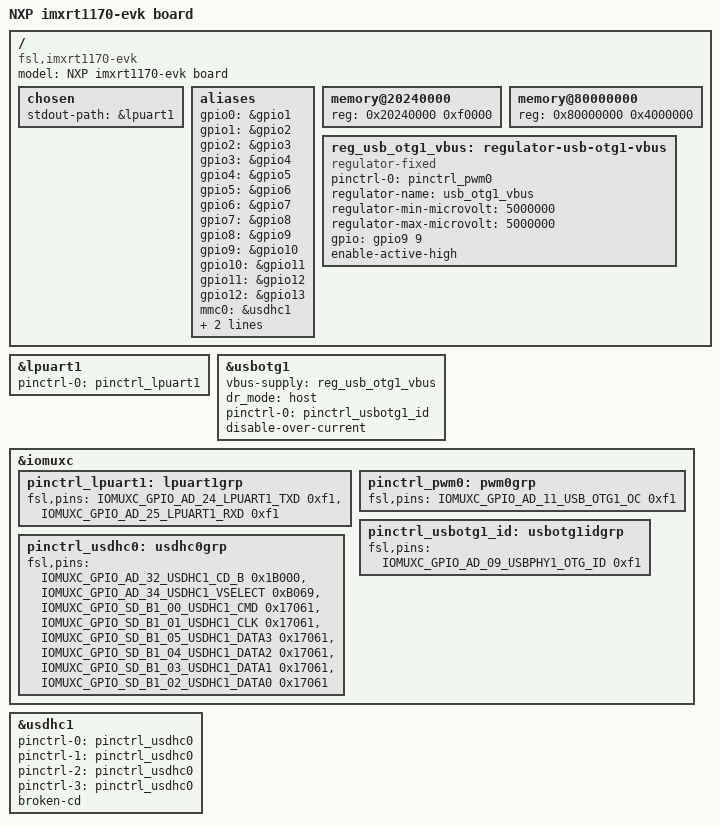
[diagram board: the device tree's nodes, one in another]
// SPDX-License-Identifier: (GPL-2.0+ OR BSD-3-Clause)
/*
 * Copyright (C) 2022
 * Author(s):  Jesse Taube <Mr.Bossman075@gmail.com>
 */

/dts-v1/;
#include "imxrt1170.dtsi"
#include "imxrt1170-pinfunc.h"

/ {
	model = "NXP imxrt1170-evk board";
	compatible = "fsl,imxrt1170-evk", "fsl,imxrt1170";

	chosen {
		stdout-path = &lpuart1;
	};

	aliases {
		gpio0 = &gpio1;
		gpio1 = &gpio2;
		gpio2 = &gpio3;
		gpio3 = &gpio4;
		gpio4 = &gpio5;
		gpio5 = &gpio6;
		gpio6 = &gpio7;
		gpio7 = &gpio8;
		gpio8 = &gpio9;
		gpio9 = &gpio10;
		gpio10 = &gpio11;
		gpio11 = &gpio12;
		gpio12 = &gpio13;
		mmc0 = &usdhc1;
		serial0 = &lpuart1;
		usbphy0 = &usbphy1;
	};

	memory@20240000 {
		device_type = "memory";
		reg = <0x20240000 0xf0000>;
	};

	memory@80000000 {
		device_type = "memory";
		reg = <0x80000000 0x4000000>;
	};

	reg_usb_otg1_vbus: regulator-usb-otg1-vbus {
		compatible = "regulator-fixed";
		pinctrl-names = "default";
		pinctrl-0 = <&pinctrl_pwm0>;
		regulator-name = "usb_otg1_vbus";
		regulator-min-microvolt = <5000000>;
		regulator-max-microvolt = <5000000>;
		gpio = <&gpio9 9 GPIO_ACTIVE_HIGH>;
		enable-active-high;
	};
};

&lpuart1 { /* console */
	pinctrl-names = "default";
	pinctrl-0 = <&pinctrl_lpuart1>;
	status = "okay";
};


&usbotg1 {
	vbus-supply = <&reg_usb_otg1_vbus>;
	dr_mode = "host";
	pinctrl-names = "default";
	pinctrl-0 = <&pinctrl_usbotg1_id>;
	disable-over-current;
	status = "okay";
};

&iomuxc {
	pinctrl_lpuart1: lpuart1grp {
		fsl,pins = <IOMUXC_GPIO_AD_24_LPUART1_TXD 0xf1>,
			   <IOMUXC_GPIO_AD_25_LPUART1_RXD 0xf1>;
	};

	pinctrl_pwm0: pwm0grp {
		fsl,pins = <IOMUXC_GPIO_AD_11_USB_OTG1_OC 0xf1>;
	};

	pinctrl_usbotg1_id: usbotg1idgrp {
		fsl,pins = <IOMUXC_GPIO_AD_09_USBPHY1_OTG_ID 0xf1>;
	};

	pinctrl_usdhc0: usdhc0grp {
		fsl,pins = <IOMUXC_GPIO_AD_32_USDHC1_CD_B		0x1B000>,
			   <IOMUXC_GPIO_AD_34_USDHC1_VSELECT		0xB069>,
			   <IOMUXC_GPIO_SD_B1_00_USDHC1_CMD		0x17061>,
			   <IOMUXC_GPIO_SD_B1_01_USDHC1_CLK		0x17061>,
			   <IOMUXC_GPIO_SD_B1_05_USDHC1_DATA3		0x17061>,
			   <IOMUXC_GPIO_SD_B1_04_USDHC1_DATA2		0x17061>,
			   <IOMUXC_GPIO_SD_B1_03_USDHC1_DATA1		0x17061>,
			   <IOMUXC_GPIO_SD_B1_02_USDHC1_DATA0		0x17061>;
	};
};

&usdhc1 {
	pinctrl-names = "default", "state_100mhz", "state_200mhz", "sleep";
	pinctrl-0 = <&pinctrl_usdhc0>;
	pinctrl-1 = <&pinctrl_usdhc0>;
	pinctrl-2 = <&pinctrl_usdhc0>;
	pinctrl-3 = <&pinctrl_usdhc0>;
	status = "okay";
	broken-cd;
};
